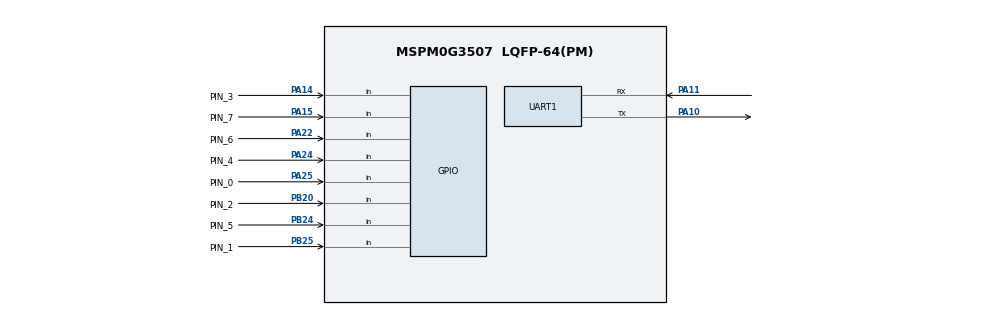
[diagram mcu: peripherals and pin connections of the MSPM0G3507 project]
/**
 * These arguments were used when this file was generated. They will be automatically applied on subsequent loads
 * via the GUI or CLI. Run CLI with '--help' for additional information on how to override these arguments.
 * @cliArgs --device "MSPM0G350X" --part "Default" --package "LQFP-64(PM)" --product "mspm0_sdk@2.11.00.07"
 * @v2CliArgs --device "MSPM0G3507" --package "LQFP-64(PM)" --product "mspm0_sdk@2.11.00.07"
 * @versions {"tool":"1.26.2+4477"}
 */

/**
 * Import the modules used in this configuration.
 */
const GPIO   = scripting.addModule("/ti/driverlib/GPIO", {}, false);
const GPIO1  = GPIO.addInstance();
const SYSCTL = scripting.addModule("/ti/driverlib/SYSCTL");
const UART   = scripting.addModule("/ti/driverlib/UART", {}, false);
const UART1  = UART.addInstance();

/**
 * Write custom configuration values to the imported modules.
 */
GPIO1.$name                         = "GPIO_SENSOR";
GPIO1.associatedPins.create(8);
GPIO1.associatedPins[0].$name       = "PIN_0";
GPIO1.associatedPins[0].direction   = "INPUT";
GPIO1.associatedPins[0].pin.$assign = "PA25";
GPIO1.associatedPins[1].$name       = "PIN_1";
GPIO1.associatedPins[1].direction   = "INPUT";
GPIO1.associatedPins[1].pin.$assign = "PB25";
GPIO1.associatedPins[2].$name       = "PIN_2";
GPIO1.associatedPins[2].direction   = "INPUT";
GPIO1.associatedPins[2].pin.$assign = "PB20";
GPIO1.associatedPins[3].$name       = "PIN_3";
GPIO1.associatedPins[3].direction   = "INPUT";
GPIO1.associatedPins[3].pin.$assign = "PA14";
GPIO1.associatedPins[4].$name       = "PIN_4";
GPIO1.associatedPins[4].direction   = "INPUT";
GPIO1.associatedPins[4].pin.$assign = "PA24";
GPIO1.associatedPins[5].$name       = "PIN_5";
GPIO1.associatedPins[5].direction   = "INPUT";
GPIO1.associatedPins[5].pin.$assign = "PB24";
GPIO1.associatedPins[6].$name       = "PIN_6";
GPIO1.associatedPins[6].direction   = "INPUT";
GPIO1.associatedPins[6].pin.$assign = "PA22";
GPIO1.associatedPins[7].$name       = "PIN_7";
GPIO1.associatedPins[7].direction   = "INPUT";
GPIO1.associatedPins[7].pin.$assign = "PA15";

const Board = scripting.addModule("/ti/driverlib/Board", {}, false);

SYSCTL.clockTreeEn           = true;
SYSCTL.forceDefaultClkConfig = true;

UART1.$name                             = "UART_0";
UART1.enableFIFO                        = true;
UART1.rxFifoThreshold                   = "DL_UART_RX_FIFO_LEVEL_ONE_ENTRY";
UART1.enableDMARX                       = false;
UART1.txFifoThreshold                   = "DL_UART_TX_FIFO_LEVEL_ONE_ENTRY";
UART1.enabledDMATXTriggers              = "DL_UART_DMA_INTERRUPT_TX";
UART1.enabledInterrupts                 = ["DMA_DONE_TX","EOT_DONE","RX"];
UART1.peripheral.$assign                = "UART0";
UART1.peripheral.rxPin.$assign          = "PA11";
UART1.peripheral.txPin.$assign          = "PA10";
UART1.txPinConfig.$name                 = "ti_driverlib_gpio_GPIOPinGeneric0";
UART1.rxPinConfig.$name                 = "ti_driverlib_gpio_GPIOPinGeneric1";
UART1.DMA_CHANNEL_TX.$name              = "DMA_CH0";
UART1.DMA_CHANNEL_TX.addressMode        = "b2f";
UART1.DMA_CHANNEL_TX.dstLength          = "BYTE";
UART1.DMA_CHANNEL_TX.srcLength          = "BYTE";
UART1.DMA_CHANNEL_TX.peripheral.$assign = "DMA_CH0";

/**
 * Pinmux solution for unlocked pins/peripherals. This ensures that minor changes to the automatic solver in a future
 * version of the tool will not impact the pinmux you originally saw.  These lines can be completely deleted in order to
 * re-solve from scratch.
 */
Board.peripheral.$suggestSolution          = "DEBUGSS";
Board.peripheral.swclkPin.$suggestSolution = "PA20";
Board.peripheral.swdioPin.$suggestSolution = "PA19";
